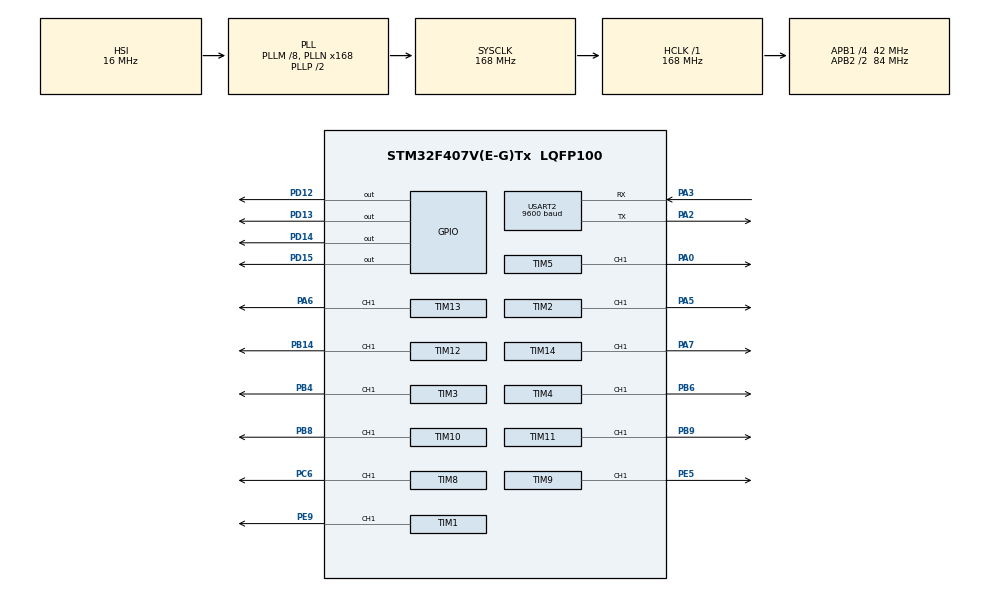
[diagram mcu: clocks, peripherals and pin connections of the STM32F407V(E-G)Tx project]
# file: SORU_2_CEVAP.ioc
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Mcu.Family=STM32F4
Mcu.Name=STM32F407V(E-G)Tx
Mcu.Package=LQFP100
NVIC.PriorityGroup=NVIC_PRIORITYGROUP_4
PA0-WKUP.Signal=S_TIM5_CH1
PA13.Mode=Serial_Wire
PA13.Signal=SYS_JTMS-SWDIO
PA14.Mode=Serial_Wire
PA14.Signal=SYS_JTCK-SWCLK
PA2.Mode=Asynchronous
PA2.Signal=USART2_TX
PA3.Mode=Asynchronous
PA3.Signal=USART2_RX
PA5.Signal=S_TIM2_CH1_ETR
PA6.Signal=S_TIM13_CH1
PA7.Signal=S_TIM14_CH1
PB14.Signal=S_TIM12_CH1
PB3.Signal=SYS_JTDO-SWO
PB4.Signal=S_TIM3_CH1
PB6.Signal=S_TIM4_CH1
PB8.Signal=S_TIM10_CH1
PB9.Signal=S_TIM11_CH1
PC6.Signal=S_TIM8_CH1
PD12.Signal=GPIO_Output
PD13.Signal=GPIO_Output
PD14.Signal=GPIO_Output
PD15.Signal=GPIO_Output
PE5.Signal=S_TIM9_CH1
PE9.Signal=S_TIM1_CH1
PH0-OSC_IN.Mode=HSE-External-Oscillator
PH0-OSC_IN.Signal=RCC_OSC_IN
PH1-OSC_OUT.Mode=HSE-External-Oscillator
PH1-OSC_OUT.Signal=RCC_OSC_OUT
ProjectManager.HeapSize=0x200
ProjectManager.StackSize=0x400
ProjectManager.TargetToolchain=STM32CubeIDE
RCC.48MHZClocksFreq_Value=84000000
RCC.AHBFreq_Value=168000000
RCC.APB1CLKDivider=RCC_HCLK_DIV4
RCC.APB1Freq_Value=42000000
RCC.APB1TimFreq_Value=84000000
RCC.APB2CLKDivider=RCC_HCLK_DIV2
RCC.APB2Freq_Value=84000000
RCC.APB2TimFreq_Value=168000000
RCC.CortexFreq_Value=168000000
RCC.HCLKFreq_Value=168000000
RCC.HSE_VALUE=25000000
RCC.HSI_VALUE=16000000
RCC.LSE_VALUE=32768
RCC.PLLM=8
RCC.PLLN=168
RCC.SYSCLKFreq_VALUE=168000000
RCC.SYSCLKSource=RCC_SYSCLKSOURCE_PLLCLK
RCC.VCOOutputFreq_Value=336000000
SH.S_TIM10_CH1.0=TIM10_CH1,Output Compare1 CH1
SH.S_TIM11_CH1.0=TIM11_CH1,Output Compare1 CH1
SH.S_TIM12_CH1.0=TIM12_CH1,Output Compare1 CH1
SH.S_TIM13_CH1.0=TIM13_CH1,Output Compare1 CH1
SH.S_TIM14_CH1.0=TIM14_CH1,Output Compare1 CH1
SH.S_TIM1_CH1.0=TIM1_CH1,Output Compare1 CH1
SH.S_TIM2_CH1_ETR.0=TIM2_CH1,Output Compare1 CH1
SH.S_TIM3_CH1.0=TIM3_CH1,Output Compare1 CH1
SH.S_TIM4_CH1.0=TIM4_CH1,Output Compare1 CH1
SH.S_TIM5_CH1.0=TIM5_CH1,Output Compare1 CH1
SH.S_TIM8_CH1.0=TIM8_CH1,Output Compare1 CH1
SH.S_TIM9_CH1.0=TIM9_CH1,Output Compare1 CH1
TIM1.Channel-Output\ Compare1\ CH1=TIM_CHANNEL_1
TIM10.Channel=TIM_CHANNEL_1
TIM11.Channel=TIM_CHANNEL_1
TIM12.Channel-Output\ Compare1\ CH1=TIM_CHANNEL_1
TIM13.Channel=TIM_CHANNEL_1
TIM14.Channel=TIM_CHANNEL_1
TIM2.Channel-Output\ Compare1\ CH1=TIM_CHANNEL_1
TIM3.Channel-Output\ Compare1\ CH1=TIM_CHANNEL_1
TIM4.Channel-Output\ Compare1\ CH1=TIM_CHANNEL_1
TIM5.Channel-Output\ Compare1\ CH1=TIM_CHANNEL_1
TIM8.Channel-Output\ Compare1\ CH1=TIM_CHANNEL_1
TIM9.Channel-Output\ Compare1\ CH1=TIM_CHANNEL_1
USART2.BaudRate=9600
USART2.VirtualMode=VM_ASYNC
VP_TIM10_VS_ClockSourceINT.Mode=Enable_Timer
VP_TIM11_VS_ClockSourceINT.Mode=Enable_Timer
VP_TIM13_VS_ClockSourceINT.Mode=Enable_Timer
VP_TIM14_VS_ClockSourceINT.Mode=Enable_Timer
VP_TIM6_VS_ClockSourceINT.Mode=Enable_Timer
VP_TIM7_VS_ClockSourceINT.Mode=Enable_Timer
board=custom

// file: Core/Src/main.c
/* USER CODE BEGIN Header */
/**
  ******************************************************************************
  * @file           : main.c
  * @brief          : Main program body
  * @AUTHOR         : MUSTAFA ERGÜL
  ******************************************************************************
  * @attention
  *
  * Copyright (c) 2023 STMicroelectronics.
  * All rights reserved.
  *
  * This software is licensed under terms that can be found in the LICENSE file
  * in the root directory of this software component.
  * If no LICENSE file comes with this software, it is provided AS-IS.
  *
  ******************************************************************************
  */
/* USER CODE END Header */
#include "main.h"

/* USER CODE BEGIN Includes */
#include <stdio.h>
#include <string.h>
#include "parser.h"
/* USER CODE END Includes */

TIM_HandleTypeDef htim1;
TIM_HandleTypeDef htim2;
TIM_HandleTypeDef htim3;
TIM_HandleTypeDef htim4;
TIM_HandleTypeDef htim5;
TIM_HandleTypeDef htim6;
TIM_HandleTypeDef htim7;
TIM_HandleTypeDef htim8;
TIM_HandleTypeDef htim9;
TIM_HandleTypeDef htim10;
TIM_HandleTypeDef htim11;
TIM_HandleTypeDef htim12;
TIM_HandleTypeDef htim13;
TIM_HandleTypeDef htim14;

UART_HandleTypeDef huart2;

void SystemClock_Config(void);
static void MX_GPIO_Init(void);
static void MX_USART2_UART_Init(void);
static void MX_TIM1_Init(void);
static void MX_TIM2_Init(void);
static void MX_TIM3_Init(void);
static void MX_TIM4_Init(void);
static void MX_TIM5_Init(void);
static void MX_TIM6_Init(void);
static void MX_TIM7_Init(void);
static void MX_TIM8_Init(void);
static void MX_TIM9_Init(void);
static void MX_TIM10_Init(void);
static void MX_TIM11_Init(void);
static void MX_TIM12_Init(void);
static void MX_TIM13_Init(void);
static void MX_TIM14_Init(void);

/* USER CODE BEGIN 0 */
uint8_t buffer[15];
/* USER CODE END 0 */

int main(void)
{

  /* MCU Configuration--------------------------------------------------------*/

  /* Reset of all peripherals, Initializes the Flash interface and the Systick. */
  HAL_Init();

  /* Configure the system clock */
  SystemClock_Config();

  /* Initialize all configured peripherals */
  MX_GPIO_Init();
  MX_USART2_UART_Init();
  MX_TIM1_Init();
  MX_TIM2_Init();
  MX_TIM3_Init();
  MX_TIM4_Init();
  MX_TIM5_Init();
  MX_TIM6_Init();
  MX_TIM7_Init();
  MX_TIM8_Init();
  MX_TIM9_Init();
  MX_TIM10_Init();
  MX_TIM11_Init();
  MX_TIM12_Init();
  MX_TIM13_Init();
  MX_TIM14_Init();

  /* Infinite loop */
  while (1)
  {

    /* USER CODE BEGIN 3 */
	  while(!(HAL_UART_Receive(&huart2, (uint8_t*)buffer,15, 1000) == HAL_OK)); //Wait until you get the UART message
	  parserMessage(buffer); //Put command in buffer
	  HAL_Delay (500);
  }
  /* USER CODE END 3 */
}

void SystemClock_Config(void)
{
  RCC_OscInitTypeDef RCC_OscInitStruct = {0};
  RCC_ClkInitTypeDef RCC_ClkInitStruct = {0};

  /** Configure the main internal regulator output voltage
  */
  __HAL_RCC_PWR_CLK_ENABLE();
  __HAL_PWR_VOLTAGESCALING_CONFIG(PWR_REGULATOR_VOLTAGE_SCALE1);

  /** Initializes the RCC Oscillators according to the specified parameters
  * in the RCC_OscInitTypeDef structure.
  */
  RCC_OscInitStruct.OscillatorType = RCC_OSCILLATORTYPE_HSI;
  RCC_OscInitStruct.HSIState = RCC_HSI_ON;
  RCC_OscInitStruct.HSICalibrationValue = RCC_HSICALIBRATION_DEFAULT;
  RCC_OscInitStruct.PLL.PLLState = RCC_PLL_ON;
  RCC_OscInitStruct.PLL.PLLSource = RCC_PLLSOURCE_HSI;
  RCC_OscInitStruct.PLL.PLLM = 8;
  RCC_OscInitStruct.PLL.PLLN = 168;
  RCC_OscInitStruct.PLL.PLLP = RCC_PLLP_DIV2;
  RCC_OscInitStruct.PLL.PLLQ = 4;
  if (HAL_RCC_OscConfig(&RCC_OscInitStruct) != HAL_OK)
  {
    Error_Handler();
  }

  /** Initializes the CPU, AHB and APB buses clocks
  */
  RCC_ClkInitStruct.ClockType = RCC_CLOCKTYPE_HCLK|RCC_CLOCKTYPE_SYSCLK
                              |RCC_CLOCKTYPE_PCLK1|RCC_CLOCKTYPE_PCLK2;
  RCC_ClkInitStruct.SYSCLKSource = RCC_SYSCLKSOURCE_PLLCLK;
  RCC_ClkInitStruct.AHBCLKDivider = RCC_SYSCLK_DIV1;
  RCC_ClkInitStruct.APB1CLKDivider = RCC_HCLK_DIV4;
  RCC_ClkInitStruct.APB2CLKDivider = RCC_HCLK_DIV2;

  if (HAL_RCC_ClockConfig(&RCC_ClkInitStruct, FLASH_LATENCY_5) != HAL_OK)
  {
    Error_Handler();
  }
}

static void MX_TIM1_Init(void)
{

  TIM_MasterConfigTypeDef sMasterConfig = {0};
  TIM_OC_InitTypeDef sConfigOC = {0};
  TIM_BreakDeadTimeConfigTypeDef sBreakDeadTimeConfig = {0};

  htim1.Instance = TIM1;
  htim1.Init.Prescaler = 0;
  htim1.Init.CounterMode = TIM_COUNTERMODE_UP;
  htim1.Init.Period = 65535;
  htim1.Init.ClockDivision = TIM_CLOCKDIVISION_DIV1;
  htim1.Init.RepetitionCounter = 0;
  htim1.Init.AutoReloadPreload = TIM_AUTORELOAD_PRELOAD_DISABLE;
  if (HAL_TIM_OC_Init(&htim1) != HAL_OK)
  {
    Error_Handler();
  }
  sMasterConfig.MasterOutputTrigger = TIM_TRGO_RESET;
  sMasterConfig.MasterSlaveMode = TIM_MASTERSLAVEMODE_DISABLE;
  if (HAL_TIMEx_MasterConfigSynchronization(&htim1, &sMasterConfig) != HAL_OK)
  {
    Error_Handler();
  }
  sConfigOC.OCMode = TIM_OCMODE_TIMING;
  sConfigOC.Pulse = 0;
  sConfigOC.OCPolarity = TIM_OCPOLARITY_HIGH;
  sConfigOC.OCNPolarity = TIM_OCNPOLARITY_HIGH;
  sConfigOC.OCFastMode = TIM_OCFAST_DISABLE;
  sConfigOC.OCIdleState = TIM_OCIDLESTATE_RESET;
  sConfigOC.OCNIdleState = TIM_OCNIDLESTATE_RESET;
  if (HAL_TIM_OC_ConfigChannel(&htim1, &sConfigOC, TIM_CHANNEL_1) != HAL_OK)
  {
    Error_Handler();
  }
  sBreakDeadTimeConfig.OffStateRunMode = TIM_OSSR_DISABLE;
  sBreakDeadTimeConfig.OffStateIDLEMode = TIM_OSSI_DISABLE;
  sBreakDeadTimeConfig.LockLevel = TIM_LOCKLEVEL_OFF;
  sBreakDeadTimeConfig.DeadTime = 0;
  sBreakDeadTimeConfig.BreakState = TIM_BREAK_DISABLE;
  sBreakDeadTimeConfig.BreakPolarity = TIM_BREAKPOLARITY_HIGH;
  sBreakDeadTimeConfig.AutomaticOutput = TIM_AUTOMATICOUTPUT_DISABLE;
  if (HAL_TIMEx_ConfigBreakDeadTime(&htim1, &sBreakDeadTimeConfig) != HAL_OK)
  {
    Error_Handler();
  }
  HAL_TIM_MspPostInit(&htim1);

}

static void MX_TIM2_Init(void)
{

  TIM_MasterConfigTypeDef sMasterConfig = {0};
  TIM_OC_InitTypeDef sConfigOC = {0};

  htim2.Instance = TIM2;
  htim2.Init.Prescaler = 0;
  htim2.Init.CounterMode = TIM_COUNTERMODE_UP;
  htim2.Init.Period = 4294967295;
  htim2.Init.ClockDivision = TIM_CLOCKDIVISION_DIV1;
  htim2.Init.AutoReloadPreload = TIM_AUTORELOAD_PRELOAD_DISABLE;
  if (HAL_TIM_OC_Init(&htim2) != HAL_OK)
  {
    Error_Handler();
  }
  sMasterConfig.MasterOutputTrigger = TIM_TRGO_RESET;
  sMasterConfig.MasterSlaveMode = TIM_MASTERSLAVEMODE_DISABLE;
  if (HAL_TIMEx_MasterConfigSynchronization(&htim2, &sMasterConfig) != HAL_OK)
  {
    Error_Handler();
  }
  sConfigOC.OCMode = TIM_OCMODE_TIMING;
  sConfigOC.Pulse = 0;
  sConfigOC.OCPolarity = TIM_OCPOLARITY_HIGH;
  sConfigOC.OCFastMode = TIM_OCFAST_DISABLE;
  if (HAL_TIM_OC_ConfigChannel(&htim2, &sConfigOC, TIM_CHANNEL_1) != HAL_OK)
  {
    Error_Handler();
  }
  HAL_TIM_MspPostInit(&htim2);

}

static void MX_TIM3_Init(void)
{

  TIM_MasterConfigTypeDef sMasterConfig = {0};
  TIM_OC_InitTypeDef sConfigOC = {0};

  htim3.Instance = TIM3;
  htim3.Init.Prescaler = 0;
  htim3.Init.CounterMode = TIM_COUNTERMODE_UP;
  htim3.Init.Period = 65535;
  htim3.Init.ClockDivision = TIM_CLOCKDIVISION_DIV1;
  htim3.Init.AutoReloadPreload = TIM_AUTORELOAD_PRELOAD_DISABLE;
  if (HAL_TIM_OC_Init(&htim3) != HAL_OK)
  {
    Error_Handler();
  }
  sMasterConfig.MasterOutputTrigger = TIM_TRGO_RESET;
  sMasterConfig.MasterSlaveMode = TIM_MASTERSLAVEMODE_DISABLE;
  if (HAL_TIMEx_MasterConfigSynchronization(&htim3, &sMasterConfig) != HAL_OK)
  {
    Error_Handler();
  }
  sConfigOC.OCMode = TIM_OCMODE_TIMING;
  sConfigOC.Pulse = 0;
  sConfigOC.OCPolarity = TIM_OCPOLARITY_HIGH;
  sConfigOC.OCFastMode = TIM_OCFAST_DISABLE;
  if (HAL_TIM_OC_ConfigChannel(&htim3, &sConfigOC, TIM_CHANNEL_1) != HAL_OK)
  {
    Error_Handler();
  }
  HAL_TIM_MspPostInit(&htim3);

}

static void MX_TIM4_Init(void)
{

  TIM_MasterConfigTypeDef sMasterConfig = {0};
  TIM_OC_InitTypeDef sConfigOC = {0};

  htim4.Instance = TIM4;
  htim4.Init.Prescaler = 0;
  htim4.Init.CounterMode = TIM_COUNTERMODE_UP;
  htim4.Init.Period = 65535;
  htim4.Init.ClockDivision = TIM_CLOCKDIVISION_DIV1;
  htim4.Init.AutoReloadPreload = TIM_AUTORELOAD_PRELOAD_DISABLE;
  if (HAL_TIM_OC_Init(&htim4) != HAL_OK)
  {
    Error_Handler();
  }
  sMasterConfig.MasterOutputTrigger = TIM_TRGO_RESET;
  sMasterConfig.MasterSlaveMode = TIM_MASTERSLAVEMODE_DISABLE;
  if (HAL_TIMEx_MasterConfigSynchronization(&htim4, &sMasterConfig) != HAL_OK)
  {
    Error_Handler();
  }
  sConfigOC.OCMode = TIM_OCMODE_TIMING;
  sConfigOC.Pulse = 0;
  sConfigOC.OCPolarity = TIM_OCPOLARITY_HIGH;
  sConfigOC.OCFastMode = TIM_OCFAST_DISABLE;
  if (HAL_TIM_OC_ConfigChannel(&htim4, &sConfigOC, TIM_CHANNEL_1) != HAL_OK)
  {
    Error_Handler();
  }
  HAL_TIM_MspPostInit(&htim4);

}

static void MX_TIM5_Init(void)
{

  TIM_MasterConfigTypeDef sMasterConfig = {0};
  TIM_OC_InitTypeDef sConfigOC = {0};

  htim5.Instance = TIM5;
  htim5.Init.Prescaler = 0;
  htim5.Init.CounterMode = TIM_COUNTERMODE_UP;
  htim5.Init.Period = 4294967295;
  htim5.Init.ClockDivision = TIM_CLOCKDIVISION_DIV1;
  htim5.Init.AutoReloadPreload = TIM_AUTORELOAD_PRELOAD_DISABLE;
  if (HAL_TIM_OC_Init(&htim5) != HAL_OK)
  {
    Error_Handler();
  }
  sMasterConfig.MasterOutputTrigger = TIM_TRGO_RESET;
  sMasterConfig.MasterSlaveMode = TIM_MASTERSLAVEMODE_DISABLE;
  if (HAL_TIMEx_MasterConfigSynchronization(&htim5, &sMasterConfig) != HAL_OK)
  {
    Error_Handler();
  }
  sConfigOC.OCMode = TIM_OCMODE_TIMING;
  sConfigOC.Pulse = 0;
  sConfigOC.OCPolarity = TIM_OCPOLARITY_HIGH;
  sConfigOC.OCFastMode = TIM_OCFAST_DISABLE;
  if (HAL_TIM_OC_ConfigChannel(&htim5, &sConfigOC, TIM_CHANNEL_1) != HAL_OK)
  {
    Error_Handler();
  }
  HAL_TIM_MspPostInit(&htim5);

}

static void MX_TIM6_Init(void)
{

  TIM_MasterConfigTypeDef sMasterConfig = {0};

  htim6.Instance = TIM6;
  htim6.Init.Prescaler = 0;
  htim6.Init.CounterMode = TIM_COUNTERMODE_UP;
  htim6.Init.Period = 65535;
  htim6.Init.AutoReloadPreload = TIM_AUTORELOAD_PRELOAD_DISABLE;
  if (HAL_TIM_Base_Init(&htim6) != HAL_OK)
  {
    Error_Handler();
  }
  sMasterConfig.MasterOutputTrigger = TIM_TRGO_RESET;
  sMasterConfig.MasterSlaveMode = TIM_MASTERSLAVEMODE_DISABLE;
  if (HAL_TIMEx_MasterConfigSynchronization(&htim6, &sMasterConfig) != HAL_OK)
  {
    Error_Handler();
  }

}

static void MX_TIM7_Init(void)
{

  TIM_MasterConfigTypeDef sMasterConfig = {0};

  htim7.Instance = TIM7;
  htim7.Init.Prescaler = 0;
  htim7.Init.CounterMode = TIM_COUNTERMODE_UP;
  htim7.Init.Period = 65535;
  htim7.Init.AutoReloadPreload = TIM_AUTORELOAD_PRELOAD_DISABLE;
  if (HAL_TIM_Base_Init(&htim7) != HAL_OK)
  {
    Error_Handler();
  }
  sMasterConfig.MasterOutputTrigger = TIM_TRGO_RESET;
  sMasterConfig.MasterSlaveMode = TIM_MASTERSLAVEMODE_DISABLE;
  if (HAL_TIMEx_MasterConfigSynchronization(&htim7, &sMasterConfig) != HAL_OK)
  {
    Error_Handler();
  }

}

static void MX_TIM8_Init(void)
{

  TIM_MasterConfigTypeDef sMasterConfig = {0};
  TIM_OC_InitTypeDef sConfigOC = {0};
  TIM_BreakDeadTimeConfigTypeDef sBreakDeadTimeConfig = {0};

  htim8.Instance = TIM8;
  htim8.Init.Prescaler = 0;
  htim8.Init.CounterMode = TIM_COUNTERMODE_UP;
  htim8.Init.Period = 65535;
  htim8.Init.ClockDivision = TIM_CLOCKDIVISION_DIV1;
  htim8.Init.RepetitionCounter = 0;
  htim8.Init.AutoReloadPreload = TIM_AUTORELOAD_PRELOAD_DISABLE;
  if (HAL_TIM_OC_Init(&htim8) != HAL_OK)
  {
    Error_Handler();
  }
  sMasterConfig.MasterOutputTrigger = TIM_TRGO_RESET;
  sMasterConfig.MasterSlaveMode = TIM_MASTERSLAVEMODE_DISABLE;
  if (HAL_TIMEx_MasterConfigSynchronization(&htim8, &sMasterConfig) != HAL_OK)
  {
    Error_Handler();
  }
  sConfigOC.OCMode = TIM_OCMODE_TIMING;
  sConfigOC.Pulse = 0;
  sConfigOC.OCPolarity = TIM_OCPOLARITY_HIGH;
  sConfigOC.OCNPolarity = TIM_OCNPOLARITY_HIGH;
  sConfigOC.OCFastMode = TIM_OCFAST_DISABLE;
  sConfigOC.OCIdleState = TIM_OCIDLESTATE_RESET;
  sConfigOC.OCNIdleState = TIM_OCNIDLESTATE_RESET;
  if (HAL_TIM_OC_ConfigChannel(&htim8, &sConfigOC, TIM_CHANNEL_1) != HAL_OK)
  {
    Error_Handler();
  }
  sBreakDeadTimeConfig.OffStateRunMode = TIM_OSSR_DISABLE;
  sBreakDeadTimeConfig.OffStateIDLEMode = TIM_OSSI_DISABLE;
  sBreakDeadTimeConfig.LockLevel = TIM_LOCKLEVEL_OFF;
  sBreakDeadTimeConfig.DeadTime = 0;
  sBreakDeadTimeConfig.BreakState = TIM_BREAK_DISABLE;
  sBreakDeadTimeConfig.BreakPolarity = TIM_BREAKPOLARITY_HIGH;
  sBreakDeadTimeConfig.AutomaticOutput = TIM_AUTOMATICOUTPUT_DISABLE;
  if (HAL_TIMEx_ConfigBreakDeadTime(&htim8, &sBreakDeadTimeConfig) != HAL_OK)
  {
    Error_Handler();
  }
  HAL_TIM_MspPostInit(&htim8);

}

static void MX_TIM9_Init(void)
{

  TIM_OC_InitTypeDef sConfigOC = {0};

  htim9.Instance = TIM9;
  htim9.Init.Prescaler = 0;
  htim9.Init.CounterMode = TIM_COUNTERMODE_UP;
  htim9.Init.Period = 65535;
  htim9.Init.ClockDivision = TIM_CLOCKDIVISION_DIV1;
  htim9.Init.AutoReloadPreload = TIM_AUTORELOAD_PRELOAD_DISABLE;
  if (HAL_TIM_OC_Init(&htim9) != HAL_OK)
  {
    Error_Handler();
  }
  sConfigOC.OCMode = TIM_OCMODE_TIMING;
  sConfigOC.Pulse = 0;
  sConfigOC.OCPolarity = TIM_OCPOLARITY_HIGH;
  sConfigOC.OCFastMode = TIM_OCFAST_DISABLE;
  if (HAL_TIM_OC_ConfigChannel(&htim9, &sConfigOC, TIM_CHANNEL_1) != HAL_OK)
  {
    Error_Handler();
  }
  HAL_TIM_MspPostInit(&htim9);

}

static void MX_TIM10_Init(void)
{

  TIM_OC_InitTypeDef sConfigOC = {0};

  htim10.Instance = TIM10;
  htim10.Init.Prescaler = 0;
  htim10.Init.CounterMode = TIM_COUNTERMODE_UP;
  htim10.Init.Period = 65535;
  htim10.Init.ClockDivision = TIM_CLOCKDIVISION_DIV1;
  htim10.Init.AutoReloadPreload = TIM_AUTORELOAD_PRELOAD_DISABLE;
  if (HAL_TIM_Base_Init(&htim10) != HAL_OK)
  {
    Error_Handler();
  }
  if (HAL_TIM_OC_Init(&htim10) != HAL_OK)
  {
    Error_Handler();
  }
  sConfigOC.OCMode = TIM_OCMODE_TIMING;
  sConfigOC.Pulse = 0;
  sConfigOC.OCPolarity = TIM_OCPOLARITY_HIGH;
  sConfigOC.OCFastMode = TIM_OCFAST_DISABLE;
  if (HAL_TIM_OC_ConfigChannel(&htim10, &sConfigOC, TIM_CHANNEL_1) != HAL_OK)
  {
    Error_Handler();
  }
  HAL_TIM_MspPostInit(&htim10);

}

static void MX_TIM11_Init(void)
{

  TIM_OC_InitTypeDef sConfigOC = {0};

  htim11.Instance = TIM11;
  htim11.Init.Prescaler = 0;
  htim11.Init.CounterMode = TIM_COUNTERMODE_UP;
  htim11.Init.Period = 65535;
  htim11.Init.ClockDivision = TIM_CLOCKDIVISION_DIV1;
  htim11.Init.AutoReloadPreload = TIM_AUTORELOAD_PRELOAD_DISABLE;
  if (HAL_TIM_Base_Init(&htim11) != HAL_OK)
  {
    Error_Handler();
  }
  if (HAL_TIM_OC_Init(&htim11) != HAL_OK)
  {
    Error_Handler();
  }
  sConfigOC.OCMode = TIM_OCMODE_TIMING;
  sConfigOC.Pulse = 0;
  sConfigOC.OCPolarity = TIM_OCPOLARITY_HIGH;
  sConfigOC.OCFastMode = TIM_OCFAST_DISABLE;
  if (HAL_TIM_OC_ConfigChannel(&htim11, &sConfigOC, TIM_CHANNEL_1) != HAL_OK)
  {
    Error_Handler();
  }
  HAL_TIM_MspPostInit(&htim11);

}

static void MX_TIM12_Init(void)
{

  TIM_OC_InitTypeDef sConfigOC = {0};

  htim12.Instance = TIM12;
  htim12.Init.Prescaler = 0;
  htim12.Init.CounterMode = TIM_COUNTERMODE_UP;
  htim12.Init.Period = 65535;
  htim12.Init.ClockDivision = TIM_CLOCKDIVISION_DIV1;
  htim12.Init.AutoReloadPreload = TIM_AUTORELOAD_PRELOAD_DISABLE;
  if (HAL_TIM_OC_Init(&htim12) != HAL_OK)
  {
    Error_Handler();
  }
  sConfigOC.OCMode = TIM_OCMODE_TIMING;
  sConfigOC.Pulse = 0;
  sConfigOC.OCPolarity = TIM_OCPOLARITY_HIGH;
  sConfigOC.OCFastMode = TIM_OCFAST_DISABLE;
  if (HAL_TIM_OC_ConfigChannel(&htim12, &sConfigOC, TIM_CHANNEL_1) != HAL_OK)
  {
    Error_Handler();
  }
  HAL_TIM_MspPostInit(&htim12);

}

static void MX_TIM13_Init(void)
{

  TIM_OC_InitTypeDef sConfigOC = {0};

  htim13.Instance = TIM13;
  htim13.Init.Prescaler = 0;
  htim13.Init.CounterMode = TIM_COUNTERMODE_UP;
  htim13.Init.Period = 65535;
  htim13.Init.ClockDivision = TIM_CLOCKDIVISION_DIV1;
  htim13.Init.AutoReloadPreload = TIM_AUTORELOAD_PRELOAD_DISABLE;
  if (HAL_TIM_Base_Init(&htim13) != HAL_OK)
  {
    Error_Handler();
  }
  if (HAL_TIM_OC_Init(&htim13) != HAL_OK)
  {
    Error_Handler();
  }
  sConfigOC.OCMode = TIM_OCMODE_TIMING;
  sConfigOC.Pulse = 0;
  sConfigOC.OCPolarity = TIM_OCPOLARITY_HIGH;
  sConfigOC.OCFastMode = TIM_OCFAST_DISABLE;
  if (HAL_TIM_OC_ConfigChannel(&htim13, &sConfigOC, TIM_CHANNEL_1) != HAL_OK)
  {
    Error_Handler();
  }
  HAL_TIM_MspPostInit(&htim13);

}

static void MX_TIM14_Init(void)
{

  TIM_OC_InitTypeDef sConfigOC = {0};

  htim14.Instance = TIM14;
  htim14.Init.Prescaler = 0;
  htim14.Init.CounterMode = TIM_COUNTERMODE_UP;
  htim14.Init.Period = 65535;
  htim14.Init.ClockDivision = TIM_CLOCKDIVISION_DIV1;
  htim14.Init.AutoReloadPreload = TIM_AUTORELOAD_PRELOAD_DISABLE;
  if (HAL_TIM_Base_Init(&htim14) != HAL_OK)
  {
    Error_Handler();
  }
  if (HAL_TIM_OC_Init(&htim14) != HAL_OK)
  {
    Error_Handler();
  }
  sConfigOC.OCMode = TIM_OCMODE_TIMING;
  sConfigOC.Pulse = 0;
  sConfigOC.OCPolarity = TIM_OCPOLARITY_HIGH;
  sConfigOC.OCFastMode = TIM_OCFAST_DISABLE;
  if (HAL_TIM_OC_ConfigChannel(&htim14, &sConfigOC, TIM_CHANNEL_1) != HAL_OK)
  {
    Error_Handler();
  }
  HAL_TIM_MspPostInit(&htim14);

}

static void MX_USART2_UART_Init(void)
{

  huart2.Instance = USART2;
  huart2.Init.BaudRate = 9600;
  huart2.Init.WordLength = UART_WORDLENGTH_8B;
  huart2.Init.StopBits = UART_STOPBITS_1;
  huart2.Init.Parity = UART_PARITY_NONE;
  huart2.Init.Mode = UART_MODE_TX_RX;
  huart2.Init.HwFlowCtl = UART_HWCONTROL_NONE;
  huart2.Init.OverSampling = UART_OVERSAMPLING_16;
  if (HAL_UART_Init(&huart2) != HAL_OK)
  {
    Error_Handler();
  }

}

static void MX_GPIO_Init(void)
{
  GPIO_InitTypeDef GPIO_InitStruct = {0};

  /* GPIO Ports Clock Enable */
  __HAL_RCC_GPIOE_CLK_ENABLE();
  __HAL_RCC_GPIOH_CLK_ENABLE();
  __HAL_RCC_GPIOA_CLK_ENABLE();
  __HAL_RCC_GPIOB_CLK_ENABLE();
  __HAL_RCC_GPIOD_CLK_ENABLE();
  __HAL_RCC_GPIOC_CLK_ENABLE();

  /*Configure GPIO pin Output Level */
  HAL_GPIO_WritePin(GPIOD, GPIO_PIN_12|GPIO_PIN_13|GPIO_PIN_14|GPIO_PIN_15, GPIO_PIN_RESET);

  /*Configure GPIO pins : PD12 PD13 PD14 PD15 */
  GPIO_InitStruct.Pin = GPIO_PIN_12|GPIO_PIN_13|GPIO_PIN_14|GPIO_PIN_15;
  GPIO_InitStruct.Mode = GPIO_MODE_OUTPUT_PP;
  GPIO_InitStruct.Pull = GPIO_NOPULL;
  GPIO_InitStruct.Speed = GPIO_SPEED_FREQ_LOW;
  HAL_GPIO_Init(GPIOD, &GPIO_InitStruct);

}

void Error_Handler(void)
{
  __disable_irq();
  while (1)
  {
  }
}
